VERSION "HIPBNYYYYYYYYYYYYYYYYYYYYYYYYYYYYYYYYYYYYY/4/%%%/4/'%**4YYY///"

NS_ :

BS_:

BU_:
VAL_TABLE_ vehicleClass 3 "Class-III" 2 "Class-II" 1 "Class-I" 0 "NA" ;
VAL_TABLE_ vehicleType 6 "N3" 5 "N2" 4 "N1" 3 "M3" 2 "M2" 1 "M1" ;
VAL_TABLE_ ISA_SLWF_Value 3 "E_ISA_SLWF_OVERSPEED_SOUND" 2 "E_ISA_SLWF_OVERSPEED" 1 "E_ISA_SLWF_LEGAL_SPEED" 0 "E_ISA_SLWF_NONE" ;
VAL_TABLE_ ISA_SLIF_Value 2 "E_ISA_SLIF_CONSTANT" 1 "E_ISA_SLIF_INITIAL" 0 "E_ISA_SLIF_NONE" ;
VAL_TABLE_ ISA_State 4 "E_ISA_STATE_ERROR" 3 "E_ISA_STATE_ACTIVE" 2 "E_ISA_STATE_PARTIAL_DEACTIVATION" 1 "E_ISA_STATE_FULL_DEACTIVATION" 0 "E_ISA_STATE_DISABLED" ;

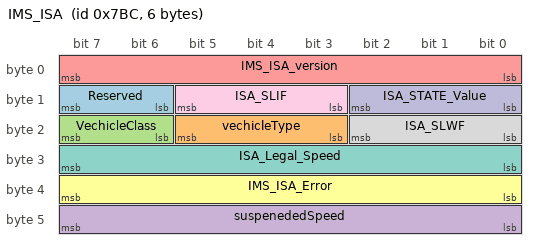
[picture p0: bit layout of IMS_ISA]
BO_ 1980 IMS_ISA: 6 Vector__XXX
 SG_ Reserved : 14|2@1+ (1,0) [0|3] "" Vector__XXX
 SG_ vechicleType : 19|3@1+ (1,0) [0|7] "" Vector__XXX
 SG_ VechicleClass : 22|2@1+ (1,0) [0|0] "" Vector__XXX
 SG_ suspenededSpeed : 40|8@1+ (1,0) [0|255] "" Vector__XXX
 SG_ IMS_ISA_version : 0|8@1+ (1,0) [0|255] "" Vector__XXX
 SG_ IMS_ISA_Error : 32|8@1+ (1,0) [0|255] "" Vector__XXX
 SG_ ISA_Legal_Speed : 24|8@1+ (1,0) [0|255] "" Vector__XXX
 SG_ ISA_SLWF : 16|3@1+ (1,0) [0|7] "" Vector__XXX
 SG_ ISA_SLIF : 11|3@1+ (1,0) [0|7] "" Vector__XXX
 SG_ ISA_STATE_Value : 8|3@1+ (1,0) [0|7] "" Vector__XXX

VAL_ 1980 vechicleType 6 "N3" 5 "N2" 4 "N1" 3 "M3" 2 "M2" 1 "M1" ;
VAL_ 1980 VechicleClass 3 "Class-III" 2 "Class-II" 1 "Class-I" 0 "NA" ;
VAL_ 1980 ISA_SLWF 3 "E_ISA_SLWF_OVERSPEED_SOUND" 2 "E_ISA_SLWF_OVERSPEED" 1 "E_ISA_SLWF_LEGAL_SPEED" 0 "E_ISA_SLWF_NONE" ;
VAL_ 1980 ISA_SLIF 4 "E_ISA_SLIF_NEW" 2 "E_ISA_SLIF_CONSTANT" 1 "E_ISA_SLIF_INITIAL" 0 "E_ISA_SLIF_NONE" ;
VAL_ 1980 ISA_STATE_Value 4 "E_ISA_STATE_ERROR" 3 "E_ISA_STATE_ACTIVE" 2 "E_ISA_STATE_PARTIAL_DEACTIVATION" 1 "E_ISA_STATE_FULL_DEACTIVATION" 0 "E_ISA_STATE_DISABLED" ;
